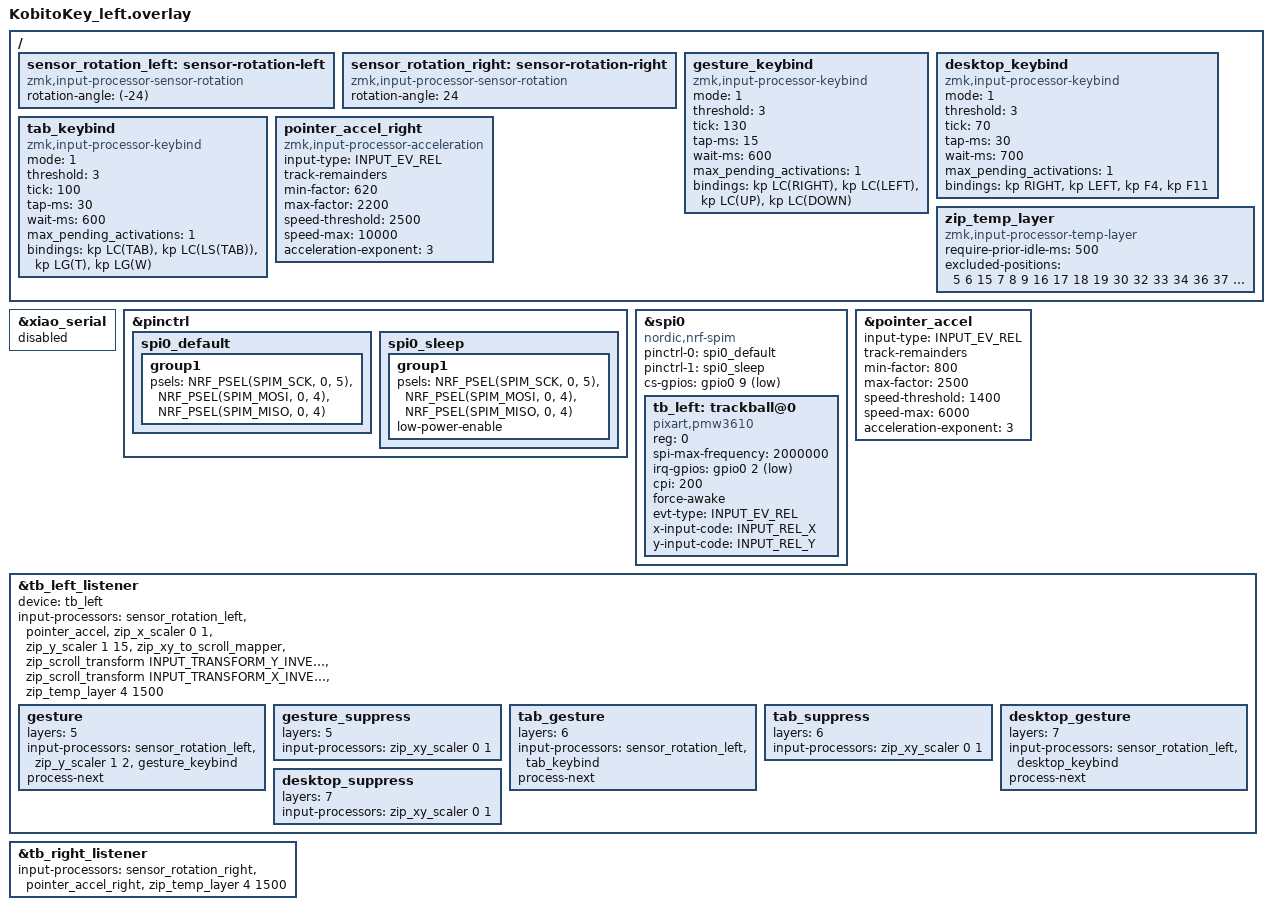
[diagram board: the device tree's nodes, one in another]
#include "kobitokey.dtsi"
#include <zephyr/dt-bindings/input/input-event-codes.h>
#include <input/processors.dtsi>
#include <input/processors/sensor_rotation.dtsi>
#include <behaviors/input_gestures_accel.dtsi>
#include <dt-bindings/zmk/keys.h>

&xiao_serial { status = "disabled"; };

&pinctrl {
    spi0_default: spi0_default {
        group1 {
            psels = <NRF_PSEL(SPIM_SCK,  0, 5)>,
                    <NRF_PSEL(SPIM_MOSI, 0, 4)>,
                    <NRF_PSEL(SPIM_MISO, 0, 4)>;
        };
    };
    spi0_sleep: spi0_sleep {
        group1 {
            psels = <NRF_PSEL(SPIM_SCK,  0, 5)>,
                    <NRF_PSEL(SPIM_MOSI, 0, 4)>,
                    <NRF_PSEL(SPIM_MISO, 0, 4)>;
            low-power-enable;
        };
    };
};

&spi0 {
    status = "okay";
    compatible = "nordic,nrf-spim";
    pinctrl-0 = <&spi0_default>;
    pinctrl-1 = <&spi0_sleep>;
    pinctrl-names = "default", "sleep";
    cs-gpios = <&gpio0 9 GPIO_ACTIVE_LOW>;

    tb_left: trackball@0 {
        status = "okay";
        compatible = "pixart,pmw3610";
        reg = <0>;
        spi-max-frequency = <2000000>;
        irq-gpios = <&gpio0 2 (GPIO_ACTIVE_LOW | GPIO_PULL_UP)>;
        cpi = <200>; /* センサー感度 */
        force-awake; /* ACTIVE中はセンサーを起こしたままにして初回操作の取りこぼしを抑える */

        evt-type = <INPUT_EV_REL>;
        x-input-code = <INPUT_REL_X>;
        y-input-code = <INPUT_REL_Y>;
    };
};

/ {
    sensor_rotation_left: sensor-rotation-left {
        compatible = "zmk,input-processor-sensor-rotation";
        status = "okay";
        #input-processor-cells = <0>;
        rotation-angle = <(-24)>;
    };

    sensor_rotation_right: sensor-rotation-right {
        compatible = "zmk,input-processor-sensor-rotation";
        #input-processor-cells = <0>;
        status = "okay";
        rotation-angle = <24>;
    };


    /* トラックボールジェスチャー用 keybind プロセッサ（Magic Trackpad 3本指スワイプ相当）
     *
     * zettaface/zmk-input-processor-keybind の実装挙動に基づく設計:
     *   - threshold: 1 イベントごとの raw 値カットオフ (低=軽い動きも拾う)
     *   - tick: 累積バケットのしきい値。tick 分溜まる毎に 1 発火
     *   - track-remainders: プロパティを「書かない」= false。発火後の余り
     *     累積を持ち越さないので、1 ストローク = 1 発火が成立しやすい
     *   - max-pending-activations = 1: 待機キューを 1 個に制限し、wait-ms
     *     中に複数発火分が溜まるのを防ぐ
     *   - wait-ms: 発火後の次発火までブロック時間。短めで反応性優先
     *   - tap-ms: キー押下時間 = 発火後の再発火チェックまでの窓。発火は
     *     スワイプ途中で起きるため、この窓内に tick 分が再蓄積すると
     *     2 連発になる。窓を 15ms に縮め、tick も 130 に上げて
     *     「勢いのあるスワイプで 2 回切り替わる」のを抑止
     *
     * 「1 スワイプ = 1 アクション、軽く触れて即反応」を狙う構成。 */
    gesture_keybind: gesture_keybind {
        compatible = "zmk,input-processor-keybind";
        #input-processor-cells = <0>;
        mode = <1>;         /* 4方向モード */
        threshold = <3>;    /* raw ノイズだけカット、軽いフリックは拾う */
        tick = <130>;       /* 1 発火に必要な累積量。100 だと強いスワイプの
                             * 残りで tap-ms 窓内に再蓄積し 2 連発したため増量 */
        tap-ms = <15>;      /* 再発火チェック窓を半減。キーが取りこぼされる
                             * ようなら 30 に戻す */
        wait-ms = <600>;    /* 発火後の release 後にブロックする時間。連続スワイプ間の最低間隔 */
        max_pending_activations = <1>;  /* max_delta = tick * 1 で蓄積を制限 */
        /* track_remainders は意図的に省略 (false) */
        bindings = <&kp LC(RIGHT)>,  /* 右: Spaces右へ */
                   <&kp LC(LEFT)>,   /* 左: Spaces左へ */
                   <&kp LC(UP)>,     /* 上: Mission Control */
                   <&kp LC(DOWN)>;   /* 下: アプリウィンドウ */
    };

    /* ブラウザタブ操作用 keybind プロセッサ */
    /* デスクトップ操作用 keybind プロセッサ（Magic Trackpad 4本指ピンチ相当）
     * F4/F11 (Launchpad / デスクトップ表示) は重い操作だが、tick を重く
     * しすぎると初回スワイプが累積不足で取りこぼされる。threshold は
     * gesture と同じ軽さ、tick は tab より低めにして 1 発目の反応を優先し、
     * wait-ms と max-pending-activations=1 で多重発火を抑える。 */
    desktop_keybind: desktop_keybind {
        compatible = "zmk,input-processor-keybind";
        #input-processor-cells = <0>;
        mode = <1>;         /* 4方向モード */
        threshold = <3>;    /* 初動の軽いフリックも拾う */
        tick = <70>;        /* 初回スワイプで発火しやすい累積量 */
        tap-ms = <30>;
        wait-ms = <700>;    /* Launchpad / Mission Control の状態遷移完了を待つ */
        max_pending_activations = <1>;  /* max_delta = tick * 1 で蓄積を制限 */
        /* track_remainders は意図的に省略 (false) */
        bindings = <&kp RIGHT>,            /* 右: Launchpad選択を右へ */
                   <&kp LEFT>,             /* 左: Launchpad選択を左へ */
                   <&kp F4>,               /* 上: Launchpad */
                   <&kp F11>;              /* 下: デスクトップを表示 */
    };

    /* ブラウザタブ操作用 keybind プロセッサ。gesture_keybind と同方針。
     * Cmd+T / Cmd+W (上下) はブラウザの状態を大きく変えるため、上下方向の
     * 取り扱いは特に慎重に。threshold は gesture と同じ 3、tick は連打を
     * 抑えるためやや高め、max-pending-activations=1 で 1 スワイプ 1 発火。 */
    tab_keybind: tab_keybind {
        compatible = "zmk,input-processor-keybind";
        #input-processor-cells = <0>;
        mode = <1>;         /* 4方向モード */
        threshold = <3>;
        tick = <100>;
        tap-ms = <30>;
        wait-ms = <600>;
        max_pending_activations = <1>;
        /* track_remainders は意図的に省略 (false) */
        bindings = <&kp LC(TAB)>,        /* 右: 次のタブ */
                   <&kp LC(LS(TAB))>,    /* 左: 前のタブ */
                   <&kp LG(T)>,          /* 上: 新規タブ */
                   <&kp LG(W)>;          /* 下: タブを閉じる */
    };

};

/* 左トラックボール加速度設定（スクロール用 / Magic Trackpad 慣性スクロール風） */
&pointer_accel {
    input-type = <INPUT_EV_REL>;
    track-remainders;
    min-factor = <800>;              /* 0.8倍: 読書時の1行スクロールが軽快 */
    max-factor = <2500>;             /* 2.5倍: y_scaler×15と掛け算で実効37.5倍 */
    speed-threshold = <1400>;        /* 立ち上がりをやや早く */
    speed-max = <6000>;
    acceleration-exponent = <3>;     /* 三次: 粘ってから急に伸びる=慣性風 */
};

/ {
    /* 右トラックボール加速度設定（ポインター用 / Magic Trackpad 風 Phase2 調整版） */
    pointer_accel_right: pointer_accel_right {
        compatible = "zmk,input-processor-acceleration";
        #input-processor-cells = <0>;
        input-type = <INPUT_EV_REL>;
        track-remainders;
        min-factor = <620>;              /* 低速をもう少しだけ短くして止めやすくする */
        max-factor = <2200>;             /* 高速域も少しだけ抑えて移動距離を短縮 */
        speed-threshold = <2500>;        /* 加速開始を遅らせて中速の粘りを強化 */
        speed-max = <10000>;             /* 高速域の伸びをなだらかにする */
        acceleration-exponent = <3>;     /* 三次: 粘ってから急に伸びるカーブ */
    };
};

&tb_left_listener {
    status = "okay";
    device = <&tb_left>;

    /* デフォルト: スクロール動作 + マウスレイヤー自動発動 */
    input-processors =
            <&sensor_rotation_left>,
            <&pointer_accel>,
            <&zip_x_scaler 0 1>,
            <&zip_y_scaler 1 15>,
            <&zip_xy_to_scroll_mapper>,
            <&zip_scroll_transform INPUT_TRANSFORM_Y_INVERT>,
            <&zip_scroll_transform INPUT_TRANSFORM_X_INVERT>,
            <&zip_temp_layer 4 1500>;

    /* Layer 5: ジェスチャーモード（keybind → Ctrl+矢印）
     * keybind の 4 方向判定はパケット単位の |dx| vs |dy| 勝者総取りで
     * 角度デッドゾーンがなく、横スワイプ中の手ブレ 1 パケットでも
     * 移動量全体が縦バケットに入って Ctrl+Up/Down が誤発火する。
     * y を 1/2 に減衰させることで、縦判定には dy > 2*dx (約63°以上) の
     * 明確な縦方向の動きを要求し、横スワイプの誤判定を抑える。
     * 副作用: 縦ジェスチャー (Mission Control 等) は約 2 倍の動きが必要 */
    gesture {
        layers = <5>;
        input-processors =
            <&sensor_rotation_left>,
            <&zip_y_scaler 1 2>,
            <&gesture_keybind>;
        process-next;
    };
    gesture_suppress {
        layers = <5>;
        input-processors = <&zip_xy_scaler 0 1>;
    };

    /* Layer 6: タブ操作モード */
    tab_gesture {
        layers = <6>;
        input-processors =
            <&sensor_rotation_left>,
            <&tab_keybind>;
        process-next;
    };
    tab_suppress {
        layers = <6>;
        input-processors = <&zip_xy_scaler 0 1>;
    };

    /* Layer 7: デスクトップ操作モード */
    desktop_gesture {
        layers = <7>;
        input-processors =
            <&sensor_rotation_left>,
            <&desktop_keybind>;
        process-next;
    };
    desktop_suppress {
        layers = <7>;
        input-processors = <&zip_xy_scaler 0 1>;
    };

    /* Layer 9: ズーム操作モード
     * keymap側の zoom_hold が LCMD を保持するので、左トラックボールは
     * 通常スクロール扱いで OS に到達 → macOS / Figma / ブラウザは
     * Cmd+スクロール = 連続ズームと解釈する（Magic Trackpad ピンチ風）
     * Layer 9 分岐は何もしない（デフォルトのスクロール処理に任せる） */
};

/ {
  /omit-if-no-ref/ zip_temp_layer: zip_temp_layer {
    compatible = "zmk,input-processor-temp-layer";
    #input-processor-cells = <2>;
    require-prior-idle-ms = <500>; /* キー押下後、何msオートマウスレイヤに入らないようにするか、誤爆防止 */
  };
};

&tb_right_listener {
    status = "okay";

    input-processors =
        <&sensor_rotation_right>,
        <&pointer_accel_right>,
        <&zip_temp_layer 4 1500>; /* オートマウスレイヤー4と滞留時間(ms)。短いほどボール離脱後すぐ通常入力に戻る */
};

&zip_temp_layer {
    excluded-positions = <
        5
        6
        15
        7
        8
        9
        16
        17
        18
        19
        30
        32
        33
        34
        36
        37
        39
    >;
};
